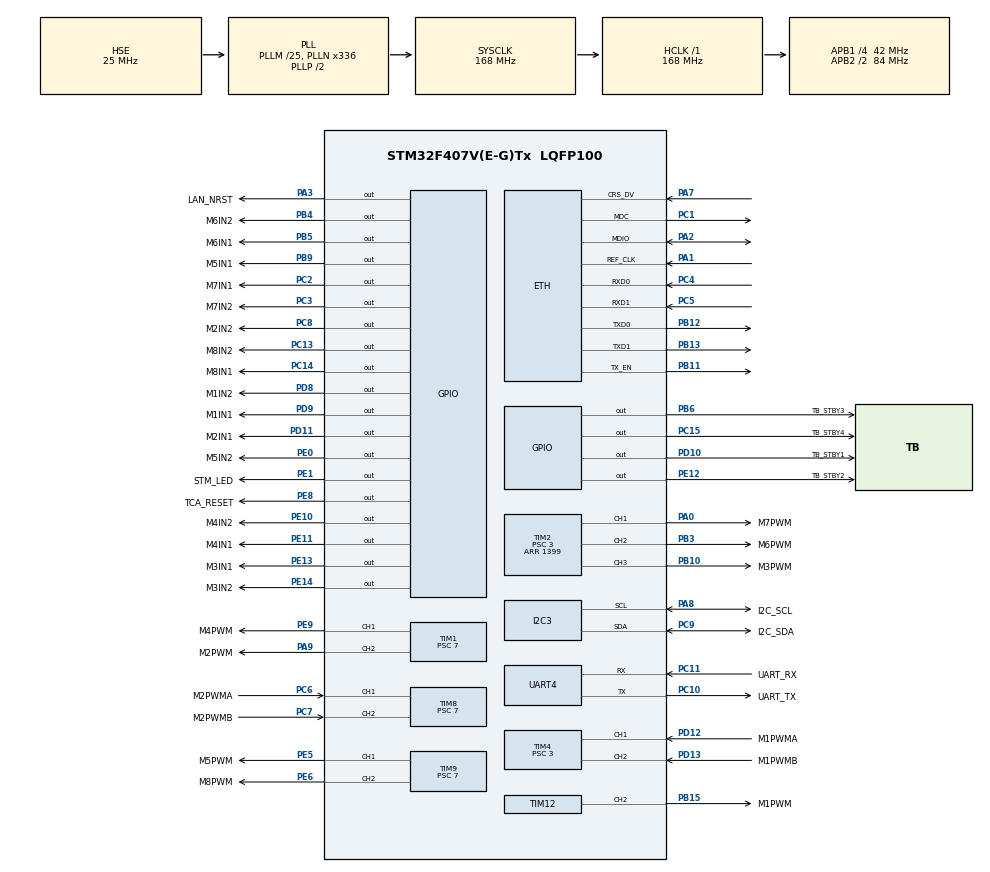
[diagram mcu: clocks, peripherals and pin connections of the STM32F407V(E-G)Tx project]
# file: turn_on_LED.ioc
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ETH.MediaInterface=HAL_ETH_RMII_MODE
Mcu.Family=STM32F4
Mcu.Name=STM32F407V(E-G)Tx
Mcu.Package=LQFP100
NVIC.PriorityGroup=NVIC_PRIORITYGROUP_4
PA0-WKUP.GPIO_Label=M7PWM
PA0-WKUP.Signal=S_TIM2_CH1_ETR
PA1.Mode=RMII
PA1.Signal=ETH_REF_CLK
PA2.Mode=RMII
PA2.Signal=ETH_MDIO
PA3.GPIO_Label=LAN_NRST
PA3.Signal=GPIO_Output
PA7.Mode=RMII
PA7.Signal=ETH_CRS_DV
PA8.GPIO_Label=I2C_SCL
PA8.Mode=I2C
PA8.Signal=I2C3_SCL
PA9.GPIO_Label=M2PWM
PA9.Signal=S_TIM1_CH2
PB10.GPIO_Label=M3PWM
PB10.Signal=S_TIM2_CH3
PB11.Mode=RMII
PB11.Signal=ETH_TX_EN
PB12.Mode=RMII
PB12.Signal=ETH_TXD0
PB13.Mode=RMII
PB13.Signal=ETH_TXD1
PB15.GPIO_Label=M1PWM
PB15.Signal=S_TIM12_CH2
PB3.GPIO_Label=M6PWM
PB3.Signal=S_TIM2_CH2
PB4.GPIO_Label=M6IN2
PB4.Signal=GPIO_Output
PB5.GPIO_Label=M6IN1
PB5.Signal=GPIO_Output
PB6.GPIO_Label=TB_STBY3
PB6.Signal=GPIO_Output
PB9.GPIO_Label=M5IN1
PB9.Signal=GPIO_Output
PC1.Mode=RMII
PC1.Signal=ETH_MDC
PC10.GPIO_Label=UART_TX
PC10.Mode=Asynchronous
PC10.Signal=UART4_TX
PC11.GPIO_Label=UART_RX
PC11.Mode=Asynchronous
PC11.Signal=UART4_RX
PC13-ANTI_TAMP.GPIO_Label=M8IN2
PC13-ANTI_TAMP.Signal=GPIO_Output
PC14-OSC32_IN.GPIO_Label=M8IN1
PC14-OSC32_IN.Signal=GPIO_Output
PC15-OSC32_OUT.GPIO_Label=TB_STBY4
PC15-OSC32_OUT.Signal=GPIO_Output
PC2.GPIO_Label=M7IN1
PC2.Signal=GPIO_Output
PC3.GPIO_Label=M7IN2
PC3.Signal=GPIO_Output
PC4.Mode=RMII
PC4.Signal=ETH_RXD0
PC5.Mode=RMII
PC5.Signal=ETH_RXD1
PC6.GPIO_Label=M2PWMA
PC6.Signal=S_TIM8_CH1
PC7.GPIO_Label=M2PWMB
PC7.Signal=S_TIM8_CH2
PC8.GPIO_Label=M2IN2
PC8.Signal=GPIO_Output
PC9.GPIO_Label=I2C_SDA
PC9.Mode=I2C
PC9.Signal=I2C3_SDA
PD10.GPIO_Label=TB_STBY1
PD10.Signal=GPIO_Output
PD11.GPIO_Label=M2IN1
PD11.Signal=GPIO_Output
PD12.GPIO_Label=M1PWMA
PD12.Signal=S_TIM4_CH1
PD13.GPIO_Label=M1PWMB
PD13.Signal=S_TIM4_CH2
PD8.GPIO_Label=M1IN2
PD8.Signal=GPIO_Output
PD9.GPIO_Label=M1IN1
PD9.Signal=GPIO_Output
PE0.GPIO_Label=M5IN2
PE0.Signal=GPIO_Output
PE1.GPIO_Label=STM_LED
PE1.Signal=GPIO_Output
PE10.GPIO_Label=M4IN2
PE10.Signal=GPIO_Output
PE11.GPIO_Label=M4IN1
PE11.Signal=GPIO_Output
PE12.GPIO_Label=TB_STBY2
PE12.Signal=GPIO_Output
PE13.GPIO_Label=M3IN1
PE13.Signal=GPIO_Output
PE14.GPIO_Label=M3IN2
PE14.Signal=GPIO_Output
PE5.GPIO_Label=M5PWM
PE5.Signal=S_TIM9_CH1
PE6.GPIO_Label=M8PWM
PE6.Signal=S_TIM9_CH2
PE8.GPIO_Label=TCA_RESET
PE8.Signal=GPIO_Output
PE9.GPIO_Label=M4PWM
PE9.Signal=S_TIM1_CH1
PH0-OSC_IN.Mode=HSE-External-Oscillator
PH0-OSC_IN.Signal=RCC_OSC_IN
PH1-OSC_OUT.Mode=HSE-External-Oscillator
PH1-OSC_OUT.Signal=RCC_OSC_OUT
ProjectManager.HeapSize=0x200
ProjectManager.StackSize=0x400
ProjectManager.TargetToolchain=STM32CubeIDE
RCC.48MHZClocksFreq_Value=84000000
RCC.AHBFreq_Value=168000000
RCC.APB1CLKDivider=RCC_HCLK_DIV4
RCC.APB1Freq_Value=42000000
RCC.APB1TimFreq_Value=84000000
RCC.APB2CLKDivider=RCC_HCLK_DIV2
RCC.APB2Freq_Value=84000000
RCC.APB2TimFreq_Value=168000000
RCC.CortexFreq_Value=168000000
RCC.HCLKFreq_Value=168000000
RCC.HSE_VALUE=25000000
RCC.HSI_VALUE=16000000
RCC.LSE_VALUE=32768
RCC.PLLM=25
RCC.PLLN=336
RCC.PLLSourceVirtual=RCC_PLLSOURCE_HSE
RCC.SYSCLKFreq_VALUE=168000000
RCC.SYSCLKSource=RCC_SYSCLKSOURCE_PLLCLK
RCC.VCOOutputFreq_Value=336000000
SH.S_TIM12_CH2.0=TIM12_CH2,PWM Generation2 CH2
SH.S_TIM1_CH1.0=TIM1_CH1,PWM Generation1 CH1
SH.S_TIM1_CH2.0=TIM1_CH2,PWM Generation2 CH2
SH.S_TIM2_CH1_ETR.0=TIM2_CH1,PWM Generation1 CH1
SH.S_TIM2_CH2.0=TIM2_CH2,PWM Generation2 CH2
SH.S_TIM2_CH3.0=TIM2_CH3,PWM Generation3 CH3
SH.S_TIM4_CH1.0=TIM4_CH1,Encoder_Interface
SH.S_TIM4_CH2.0=TIM4_CH2,Encoder_Interface
SH.S_TIM8_CH1.0=TIM8_CH1,Encoder_Interface
SH.S_TIM8_CH2.0=TIM8_CH2,Encoder_Interface
SH.S_TIM9_CH1.0=TIM9_CH1,PWM Generation1 CH1
SH.S_TIM9_CH2.0=TIM9_CH2,PWM Generation2 CH2
TIM1.Channel-PWM\ Generation1\ CH1=TIM_CHANNEL_1
TIM1.Channel-PWM\ Generation2\ CH2=TIM_CHANNEL_2
TIM1.Period=1399
TIM1.Prescaler=7
TIM12.Channel-PWM\ Generation2\ CH2=TIM_CHANNEL_2
TIM2.Channel-PWM\ Generation1\ CH1=TIM_CHANNEL_1
TIM2.Channel-PWM\ Generation2\ CH2=TIM_CHANNEL_2
TIM2.Channel-PWM\ Generation3\ CH3=TIM_CHANNEL_3
TIM2.Period=1399
TIM2.Prescaler=3
TIM4.Period=1399
TIM4.Prescaler=3
TIM8.Period=1399
TIM8.Prescaler=7
TIM9.Channel-PWM\ Generation1\ CH1=TIM_CHANNEL_1
TIM9.Channel-PWM\ Generation2\ CH2=TIM_CHANNEL_2
TIM9.Period=1399
TIM9.Prescaler=7
UART4.VirtualMode=Asynchronous
board=custom

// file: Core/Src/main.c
/* USER CODE BEGIN Header */
/**
  ******************************************************************************
  * @file           : main.c
  * @brief          : Main program body
  ******************************************************************************
  * @attention
  *
  * Copyright (c) 2026 STMicroelectronics.
  * All rights reserved.
  *
  * This software is licensed under terms that can be found in the LICENSE file
  * in the root directory of this software component.
  * If no LICENSE file comes with this software, it is provided AS-IS.
  *
  ******************************************************************************
  */
/* USER CODE END Header */
#include "main.h"
#include "eth.h"
#include "i2c.h"
#include "tim.h"
#include "usart.h"
#include "gpio.h"

void SystemClock_Config(void);

int main(void)
{

  /* USER CODE BEGIN 1 */
  HAL_GPIO_Write_Pin(STM_LED_GPIO_Port,STM_LED_Pin,GPIO_PIN_SET);
  /* USER CODE END 1 */

  /* MCU Configuration--------------------------------------------------------*/

  /* Reset of all peripherals, Initializes the Flash interface and the Systick. */
  HAL_Init();

  /* Configure the system clock */
  SystemClock_Config();

  /* Initialize all configured peripherals */
  MX_GPIO_Init();
  MX_ETH_Init();
  MX_I2C3_Init();
  MX_TIM1_Init();
  MX_TIM2_Init();
  MX_TIM4_Init();
  MX_TIM8_Init();
  MX_TIM9_Init();
  MX_TIM12_Init();
  MX_UART4_Init();

  /* Infinite loop */
  while (1)
  {

  }
}

void SystemClock_Config(void)
{
  RCC_OscInitTypeDef RCC_OscInitStruct = {0};
  RCC_ClkInitTypeDef RCC_ClkInitStruct = {0};

  /** Configure the main internal regulator output voltage
  */
  __HAL_RCC_PWR_CLK_ENABLE();
  __HAL_PWR_VOLTAGESCALING_CONFIG(PWR_REGULATOR_VOLTAGE_SCALE1);

  /** Initializes the RCC Oscillators according to the specified parameters
  * in the RCC_OscInitTypeDef structure.
  */
  RCC_OscInitStruct.OscillatorType = RCC_OSCILLATORTYPE_HSE;
  RCC_OscInitStruct.HSEState = RCC_HSE_ON;
  RCC_OscInitStruct.PLL.PLLState = RCC_PLL_ON;
  RCC_OscInitStruct.PLL.PLLSource = RCC_PLLSOURCE_HSE;
  RCC_OscInitStruct.PLL.PLLM = 25;
  RCC_OscInitStruct.PLL.PLLN = 336;
  RCC_OscInitStruct.PLL.PLLP = RCC_PLLP_DIV2;
  RCC_OscInitStruct.PLL.PLLQ = 4;
  if (HAL_RCC_OscConfig(&RCC_OscInitStruct) != HAL_OK)
  {
    Error_Handler();
  }

  /** Initializes the CPU, AHB and APB buses clocks
  */
  RCC_ClkInitStruct.ClockType = RCC_CLOCKTYPE_HCLK|RCC_CLOCKTYPE_SYSCLK
                              |RCC_CLOCKTYPE_PCLK1|RCC_CLOCKTYPE_PCLK2;
  RCC_ClkInitStruct.SYSCLKSource = RCC_SYSCLKSOURCE_PLLCLK;
  RCC_ClkInitStruct.AHBCLKDivider = RCC_SYSCLK_DIV1;
  RCC_ClkInitStruct.APB1CLKDivider = RCC_HCLK_DIV4;
  RCC_ClkInitStruct.APB2CLKDivider = RCC_HCLK_DIV2;

  if (HAL_RCC_ClockConfig(&RCC_ClkInitStruct, FLASH_LATENCY_5) != HAL_OK)
  {
    Error_Handler();
  }
}

void Error_Handler(void)
{
  __disable_irq();
  while (1)
  {
  }
}
